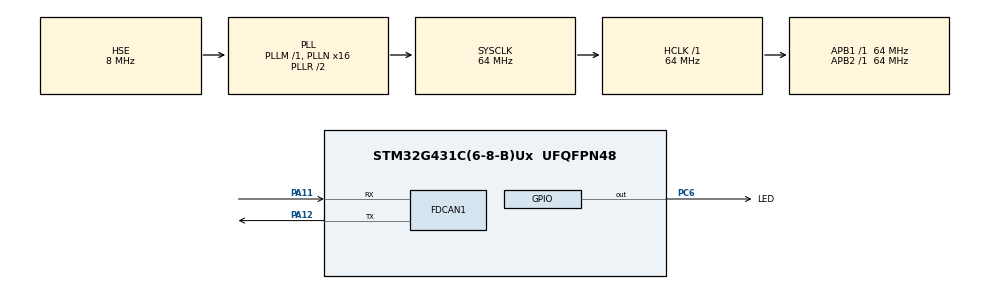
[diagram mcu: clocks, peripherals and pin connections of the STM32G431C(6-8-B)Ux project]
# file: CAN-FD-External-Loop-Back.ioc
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FDCAN1.AutoRetransmission=ENABLE
FDCAN1.CalculateBaudRateNominal=500000
FDCAN1.CalculateTimeBitNominal=2000
FDCAN1.CalculateTimeQuantumNominal=15.625
FDCAN1.ClockDivider=FDCAN_CLOCK_DIV1
FDCAN1.DataPrescaler=2
FDCAN1.DataSyncJumpWidth=8
FDCAN1.DataTimeSeg1=23
FDCAN1.DataTimeSeg2=8
FDCAN1.ExtFiltersNbr=8
FDCAN1.FrameFormat=FDCAN_FRAME_FD_BRS
FDCAN1.Mode=FDCAN_MODE_EXTERNAL_LOOPBACK
FDCAN1.NominalPrescaler=1
FDCAN1.NominalSyncJumpWidth=32
FDCAN1.NominalTimeSeg1=95
FDCAN1.NominalTimeSeg2=32
FDCAN1.StdFiltersNbr=8
FDCAN1.TransmitPause=ENABLE
Mcu.Family=STM32G4
Mcu.Name=STM32G431C(6-8-B)Ux
Mcu.Package=UFQFPN48
NVIC.PriorityGroup=NVIC_PRIORITYGROUP_4
PA11.Mode=FDCAN_Activate
PA11.Signal=FDCAN1_RX
PA12.Mode=FDCAN_Activate
PA12.Signal=FDCAN1_TX
PA13.Mode=Serial_Wire
PA13.Signal=SYS_JTMS-SWDIO
PA14.Mode=Serial_Wire
PA14.Signal=SYS_JTCK-SWCLK
PC6.GPIO_Label=LED
PC6.Signal=GPIO_Output
PF0-OSC_IN.Mode=HSE-External-Oscillator
PF0-OSC_IN.Signal=RCC_OSC_IN
PF1-OSC_OUT.Mode=HSE-External-Oscillator
PF1-OSC_OUT.Signal=RCC_OSC_OUT
ProjectManager.HeapSize=0x200
ProjectManager.StackSize=0x400
ProjectManager.TargetToolchain=STM32CubeIDE
RCC.ADC12Freq_Value=64000000
RCC.AHBFreq_Value=64000000
RCC.APB1Freq_Value=64000000
RCC.APB1TimFreq_Value=64000000
RCC.APB2Freq_Value=64000000
RCC.APB2TimFreq_Value=64000000
RCC.CortexFreq_Value=64000000
RCC.EXTERNAL_CLOCK_VALUE=12288000
RCC.HCLKFreq_Value=64000000
RCC.HSE_VALUE=8000000
RCC.HSI48_VALUE=48000000
RCC.HSI_VALUE=16000000
RCC.LSE_VALUE=32768
RCC.PLLN=16
RCC.PLLSourceVirtual=RCC_PLLSOURCE_HSE
RCC.SYSCLKFreq_VALUE=64000000
RCC.SYSCLKSource=RCC_SYSCLKSOURCE_PLLCLK
RCC.USBFreq_Value=64000000
RCC.VCOOutputFreq_Value=128000000
VP_SYS_VS_DBSignals.Mode=DisableDeadBatterySignals
board=custom

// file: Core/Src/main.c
/* USER CODE BEGIN Header */
/**
  ******************************************************************************
  * @file           : main.c
  * @brief          : Main program body
  ******************************************************************************
  * @attention
  *
  * Copyright (c) 2024 STMicroelectronics.
  * All rights reserved.
  *
  * This software is licensed under terms that can be found in the LICENSE file
  * in the root directory of this software component.
  * If no LICENSE file comes with this software, it is provided AS-IS.
  *
  ******************************************************************************
  */
/* USER CODE END Header */
#include "main.h"

FDCAN_HandleTypeDef hfdcan1;

/* USER CODE BEGIN PV */
FDCAN_FilterTypeDef sFilterConfig;
FDCAN_TxHeaderTypeDef TxHeader;
FDCAN_RxHeaderTypeDef RxHeader;
uint8_t TxData0[] = {0x10, 0x32, 0x54, 0x76, 0x98, 0x00, 0x11, 0x22, 0x33, 0x44, 0x55, 0x66};
uint8_t TxData1[] = {0x55, 0x55, 0x55, 0x55, 0x55, 0x55, 0x55, 0x55, 0x55, 0x55, 0x55, 0x55};
uint8_t TxData2[] = {0xFF, 0x00, 0xFF, 0x00, 0xFF, 0x00, 0xFF, 0x00, 0xFF, 0x00, 0xFF, 0x00};
uint8_t RxData[12];

uint32_t test_var = 0;
uint32_t FIFO0_cntr = 0;
uint32_t FIFO1_cntr = 0;

HAL_StatusTypeDef status_var = HAL_OK;
/* USER CODE END PV */

void SystemClock_Config(void);
static void MX_GPIO_Init(void);
static void MX_FDCAN1_Init(void);
/* USER CODE BEGIN PFP */
static uint32_t BufferCmp8b(uint8_t* pBuffer1, uint8_t* pBuffer2, uint16_t BufferLength);

/* USER CODE END PFP */

int main(void)
{

  /* MCU Configuration--------------------------------------------------------*/

  /* Reset of all peripherals, Initializes the Flash interface and the Systick. */
  HAL_Init();

  /* Configure the system clock */
  SystemClock_Config();

  /* Initialize all configured peripherals */
  MX_GPIO_Init();
  MX_FDCAN1_Init();
  /* USER CODE BEGIN 2 */

  /*##-1 Configure the FDCAN filters ########################################*/
  /* Configure standard ID reception filter to Rx FIFO 0 */
  sFilterConfig.IdType = FDCAN_STANDARD_ID;
  sFilterConfig.FilterIndex = 0;
  sFilterConfig.FilterType = FDCAN_FILTER_DUAL;
  sFilterConfig.FilterConfig = FDCAN_FILTER_TO_RXFIFO0;
  sFilterConfig.FilterID1 = 0x444;
  sFilterConfig.FilterID2 = 0x555;
  if (HAL_FDCAN_ConfigFilter(&hfdcan1, &sFilterConfig) != HAL_OK)
  {
    Error_Handler();
  }

  sFilterConfig.IdType = FDCAN_STANDARD_ID;
  sFilterConfig.FilterIndex = 1;
  sFilterConfig.FilterType = FDCAN_FILTER_RANGE;
  sFilterConfig.FilterConfig = FDCAN_FILTER_TO_RXFIFO0;
  sFilterConfig.FilterID1 = 0x000;
  sFilterConfig.FilterID2 = 0x7F7;
  if (HAL_FDCAN_ConfigFilter(&hfdcan1, &sFilterConfig) != HAL_OK)
  {
    Error_Handler();
  }

  /* Configure extended ID reception filter to Rx FIFO 1 */
  sFilterConfig.IdType = FDCAN_EXTENDED_ID;
  sFilterConfig.FilterIndex = 0;
  sFilterConfig.FilterType = FDCAN_FILTER_RANGE_NO_EIDM;
  sFilterConfig.FilterConfig = FDCAN_FILTER_TO_RXFIFO1;
  sFilterConfig.FilterID1 = 0x1111111;
  sFilterConfig.FilterID2 = 0x2222222;
  if (HAL_FDCAN_ConfigFilter(&hfdcan1, &sFilterConfig) != HAL_OK)
  {
    Error_Handler();
  }

  /* Configure global filter:
     Filter all remote frames with STD and EXT ID
     Reject non matching frames with STD ID and EXT ID */
  if (HAL_FDCAN_ConfigGlobalFilter(&hfdcan1, FDCAN_REJECT, FDCAN_REJECT, FDCAN_FILTER_REMOTE, FDCAN_FILTER_REMOTE) != HAL_OK)
  {
    Error_Handler();
  }

  /*##-2 Start FDCAN controller (continuous listening CAN bus) ##############*/
  if (HAL_FDCAN_Start(&hfdcan1) != HAL_OK)
  {
    Error_Handler();
  }

  /*##-3 Transmit messages ##################################################*/
  /* Add message to Tx FIFO */
  TxHeader.Identifier = 0x555;
  TxHeader.IdType = FDCAN_STANDARD_ID;
  TxHeader.TxFrameType = FDCAN_DATA_FRAME;
  TxHeader.DataLength = FDCAN_DLC_BYTES_12;
  TxHeader.ErrorStateIndicator = FDCAN_ESI_ACTIVE;
  TxHeader.BitRateSwitch = FDCAN_BRS_ON;
  TxHeader.FDFormat = FDCAN_FD_CAN;
  TxHeader.TxEventFifoControl = FDCAN_STORE_TX_EVENTS;
  TxHeader.MessageMarker = 0x52;
  if (HAL_FDCAN_AddMessageToTxFifoQ(&hfdcan1, &TxHeader, TxData0) != HAL_OK)
  {
    Error_Handler();
  }

  /* Add second message to Tx FIFO */
  TxHeader.Identifier = 0x1111112;
  TxHeader.IdType = FDCAN_EXTENDED_ID;
  TxHeader.TxFrameType = FDCAN_DATA_FRAME;
  TxHeader.DataLength = FDCAN_DLC_BYTES_12;
  TxHeader.ErrorStateIndicator = FDCAN_ESI_PASSIVE;
  TxHeader.BitRateSwitch = FDCAN_BRS_ON;
  TxHeader.FDFormat = FDCAN_FD_CAN;
  TxHeader.TxEventFifoControl = FDCAN_STORE_TX_EVENTS;
  TxHeader.MessageMarker = 0xCC;
  if (HAL_FDCAN_AddMessageToTxFifoQ(&hfdcan1, &TxHeader, TxData1) != HAL_OK)
  {
    Error_Handler();
  }

  /* Add third message to Tx FIFO */
  TxHeader.Identifier = 0x1111113;
  TxHeader.IdType = FDCAN_EXTENDED_ID;
  TxHeader.TxFrameType = FDCAN_DATA_FRAME;
  TxHeader.DataLength = FDCAN_DLC_BYTES_12;
  TxHeader.ErrorStateIndicator = FDCAN_ESI_PASSIVE;
  TxHeader.BitRateSwitch = FDCAN_BRS_OFF;
  TxHeader.FDFormat = FDCAN_FD_CAN;
  TxHeader.TxEventFifoControl = FDCAN_STORE_TX_EVENTS;
  TxHeader.MessageMarker = 0xDD;
  if (HAL_FDCAN_AddMessageToTxFifoQ(&hfdcan1, &TxHeader, TxData2) != HAL_OK)
  {
    Error_Handler();
  }

  /* Wait transmissions complete */

  while (HAL_FDCAN_GetTxFifoFreeLevel(&hfdcan1) != 3) {}

  /*##-4 Receive messages ###################################################*/
  /* Check one message is received in Rx FIFO 0 */

  FIFO0_cntr = HAL_FDCAN_GetRxFifoFillLevel(&hfdcan1, FDCAN_RX_FIFO0);
  FIFO1_cntr = HAL_FDCAN_GetRxFifoFillLevel(&hfdcan1, FDCAN_RX_FIFO1);

  if(HAL_FDCAN_GetRxFifoFillLevel(&hfdcan1, FDCAN_RX_FIFO0) != 1)
  {
    Error_Handler();
  }

  /* Retrieve message from Rx FIFO 0 */
  if (HAL_FDCAN_GetRxMessage(&hfdcan1, FDCAN_RX_FIFO0, &RxHeader, RxData) != HAL_OK)
  {
    Error_Handler();
  }

  /* Compare payload to expected data */
  if (BufferCmp8b(TxData0, RxData, 12) != 0)
  {
    Error_Handler();
  }

  /* Check two messages are received in Rx FIFO 1 */
  if(HAL_FDCAN_GetRxFifoFillLevel(&hfdcan1, FDCAN_RX_FIFO1) != 2)
  {
    Error_Handler();
  }

  /* Retrieve message from Rx FIFO 1 */
  if (HAL_FDCAN_GetRxMessage(&hfdcan1, FDCAN_RX_FIFO1, &RxHeader, RxData) != HAL_OK)
  {
    Error_Handler();
  }

  /* Compare payload to expected data */
  if (BufferCmp8b(TxData1, RxData, 12) != 0)
  {
    Error_Handler();
  }

  /* Retrieve next message from Rx FIFO 1 */
  if (HAL_FDCAN_GetRxMessage(&hfdcan1, FDCAN_RX_FIFO1, &RxHeader, RxData) != HAL_OK)
  {
    Error_Handler();
  }

  /* Compare payload to expected data */
  if (BufferCmp8b(TxData2, RxData, 12) != 0)
  {
    Error_Handler();
  }

  /* USER CODE END 2 */

  /* Infinite loop */
  while (1)
  {

  }
}

void SystemClock_Config(void)
{
  RCC_OscInitTypeDef RCC_OscInitStruct = {0};
  RCC_ClkInitTypeDef RCC_ClkInitStruct = {0};

  /** Configure the main internal regulator output voltage
  */
  HAL_PWREx_ControlVoltageScaling(PWR_REGULATOR_VOLTAGE_SCALE1);

  /** Initializes the RCC Oscillators according to the specified parameters
  * in the RCC_OscInitTypeDef structure.
  */
  RCC_OscInitStruct.OscillatorType = RCC_OSCILLATORTYPE_HSE;
  RCC_OscInitStruct.HSEState = RCC_HSE_ON;
  RCC_OscInitStruct.PLL.PLLState = RCC_PLL_ON;
  RCC_OscInitStruct.PLL.PLLSource = RCC_PLLSOURCE_HSE;
  RCC_OscInitStruct.PLL.PLLM = RCC_PLLM_DIV1;
  RCC_OscInitStruct.PLL.PLLN = 16;
  RCC_OscInitStruct.PLL.PLLP = RCC_PLLP_DIV2;
  RCC_OscInitStruct.PLL.PLLQ = RCC_PLLQ_DIV2;
  RCC_OscInitStruct.PLL.PLLR = RCC_PLLR_DIV2;
  if (HAL_RCC_OscConfig(&RCC_OscInitStruct) != HAL_OK)
  {
    Error_Handler();
  }

  /** Initializes the CPU, AHB and APB buses clocks
  */
  RCC_ClkInitStruct.ClockType = RCC_CLOCKTYPE_HCLK|RCC_CLOCKTYPE_SYSCLK
                              |RCC_CLOCKTYPE_PCLK1|RCC_CLOCKTYPE_PCLK2;
  RCC_ClkInitStruct.SYSCLKSource = RCC_SYSCLKSOURCE_PLLCLK;
  RCC_ClkInitStruct.AHBCLKDivider = RCC_SYSCLK_DIV1;
  RCC_ClkInitStruct.APB1CLKDivider = RCC_HCLK_DIV1;
  RCC_ClkInitStruct.APB2CLKDivider = RCC_HCLK_DIV1;

  if (HAL_RCC_ClockConfig(&RCC_ClkInitStruct, FLASH_LATENCY_2) != HAL_OK)
  {
    Error_Handler();
  }
}

static void MX_FDCAN1_Init(void)
{

  hfdcan1.Instance = FDCAN1;
  hfdcan1.Init.ClockDivider = FDCAN_CLOCK_DIV1;
  hfdcan1.Init.FrameFormat = FDCAN_FRAME_FD_BRS;
  hfdcan1.Init.Mode = FDCAN_MODE_EXTERNAL_LOOPBACK;
  hfdcan1.Init.AutoRetransmission = ENABLE;
  hfdcan1.Init.TransmitPause = ENABLE;
  hfdcan1.Init.ProtocolException = DISABLE;
  hfdcan1.Init.NominalPrescaler = 1;
  hfdcan1.Init.NominalSyncJumpWidth = 32;
  hfdcan1.Init.NominalTimeSeg1 = 95;
  hfdcan1.Init.NominalTimeSeg2 = 32;
  hfdcan1.Init.DataPrescaler = 2;
  hfdcan1.Init.DataSyncJumpWidth = 8;
  hfdcan1.Init.DataTimeSeg1 = 23;
  hfdcan1.Init.DataTimeSeg2 = 8;
  hfdcan1.Init.StdFiltersNbr = 8;
  hfdcan1.Init.ExtFiltersNbr = 8;
  hfdcan1.Init.TxFifoQueueMode = FDCAN_TX_FIFO_OPERATION;
  if (HAL_FDCAN_Init(&hfdcan1) != HAL_OK)
  {
    Error_Handler();
  }

}

static void MX_GPIO_Init(void)
{
  GPIO_InitTypeDef GPIO_InitStruct = {0};

  /* GPIO Ports Clock Enable */
  __HAL_RCC_GPIOF_CLK_ENABLE();
  __HAL_RCC_GPIOC_CLK_ENABLE();
  __HAL_RCC_GPIOA_CLK_ENABLE();

  /*Configure GPIO pin Output Level */
  HAL_GPIO_WritePin(LED_GPIO_Port, LED_Pin, GPIO_PIN_RESET);

  /*Configure GPIO pin : LED_Pin */
  GPIO_InitStruct.Pin = LED_Pin;
  GPIO_InitStruct.Mode = GPIO_MODE_OUTPUT_PP;
  GPIO_InitStruct.Pull = GPIO_NOPULL;
  GPIO_InitStruct.Speed = GPIO_SPEED_FREQ_LOW;
  HAL_GPIO_Init(LED_GPIO_Port, &GPIO_InitStruct);

}

/* USER CODE BEGIN 4 */

/**
  * @brief Compares two buffers.
  * @par Input
  *  - pBuffer1, pBuffer2: buffers to be compared.
  *  - BufferLength: buffer's length
  * @par Output
  * None.
  * @retval
  *   0: pBuffer1 identical to pBuffer2
  *   1: pBuffer1 differs from pBuffer2
  */
static uint32_t BufferCmp8b(uint8_t* pBuffer1, uint8_t* pBuffer2, uint16_t BufferLength)
{
  while(BufferLength--)
  {
    if(*pBuffer1 != *pBuffer2)
    {
      return 1;
    }

    pBuffer1++;
    pBuffer2++;
  }
  return 0;
}

/* USER CODE END 4 */

void Error_Handler(void)
{
  __disable_irq();
  while (1)
  {
  }
}
